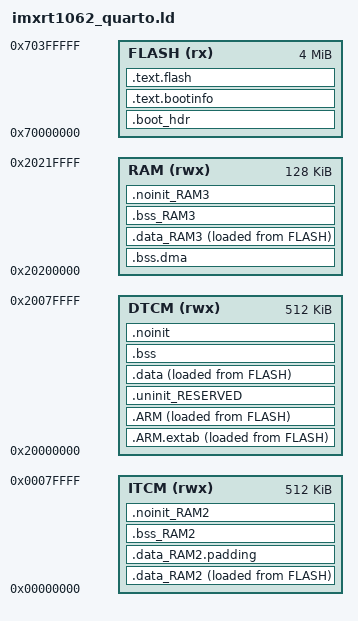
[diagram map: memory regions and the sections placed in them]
MEMORY
{
  	ITCM (rwx) : ORIGIN = 0x0, LENGTH = 0x80000      
  	DTCM (rwx) : ORIGIN = 0x20000000, LENGTH = 0x80000
  	RAM (rwx) : ORIGIN = 0x20200000, LENGTH = 0x20000
  	FLASH (rx) : ORIGIN = 0x70000000, LENGTH = 0x400000
}

ENTRY(ResetHandler)

GROUP (
  "libm.a"
  "libgcc.a"
  "libc_nano.a"
  "libstdc++.a"
 /*  "libcr_newlib_semihost.a"*/
)

SECTIONS
{
     /* Image Vector Table and Boot Data for booting from external flash */
    .boot_hdr : ALIGN(4)
    {
        FILL(0xff)
        __boot_hdr_start__ = ABSOLUTE(.) ;
        KEEP(*(.boot_hdr.conf))
        . = 0x1000 ;
        KEEP(*(.boot_hdr.ivt))
        . = 0x1020 ;
        KEEP(*(.boot_hdr.boot_data))
        . = 0x1030 ;
        KEEP(*(.boot_hdr.dcd_data))
        __boot_hdr_end__ = ABSOLUTE(.) ;
    } >FLASH

    /* MAIN TEXT SECTION */
    .text.bootinfo : ALIGN(4)
    {
        FILL(0xff)
        __vectors_start__ = ABSOLUTE(.) ;
        KEEP(*(.isr_vector))
        /* Global Section Table */
        . = ALIGN(4) ;
        __section_table_start = .;
        __data_section_table = .;
        
        
        LONG(LOADADDR(.data));
        LONG(    ADDR(.data));
        LONG(  SIZEOF(.data));
        LONG(LOADADDR(.data_RAM2));
        LONG(    ADDR(.data_RAM2));
        LONG(  SIZEOF(.data_RAM2));
        LONG(LOADADDR(.data_RAM3));
        LONG(    ADDR(.data_RAM3));
        LONG(  SIZEOF(.data_RAM3));
        __data_section_table_end = .;
        __bss_section_table = .;
        LONG(    ADDR(.bss));
        LONG(  SIZEOF(.bss));
        LONG(    ADDR(.bss_RAM2));
        LONG(  SIZEOF(.bss_RAM2));
        LONG(    ADDR(.bss_RAM3));
        LONG(  SIZEOF(.bss_RAM3));
        __bss_section_table_end = .;
        __section_table_end = . ;
        /* End of Global Section Table */
				
        *(.after_vectors*)
        *(.startup*)

    } > FLASH

    .text.flash : ALIGN(4)
    {       
       *(.progmem*)   
       *(.flashmem*)           
       . = ALIGN(4);
       
        KEEP(*(.init))
        __preinit_array_start = .;
        KEEP (*(.preinit_array))
        __preinit_array_end = .;
        __init_array_start = .;
        KEEP (*(.init_array))
        __init_array_end = .;
        . = ALIGN(16);
              
    } > FLASH
    /*
     * for exception handling/unwind - some Newlib functions (in common
     * with C++ and STDC++) use this.
     */
     
     .bss.dma (NOLOAD) : {
     	*(.dmabuffers)
     	. = ALIGN(16);
     } > RAM
     
     
     
    .ARM.extab : ALIGN(4)
    {
        *(.ARM.extab* .gnu.linkonce.armextab.*)
    } > DTCM AT >FLASH 
    
    
     .ARM : ALIGN(4)
    {
        __exidx_start = .;
        *(.ARM.exidx* .gnu.linkonce.armexidx.*)
        __exidx_end = .;
     } > DTCM AT >FLASH 
 	
     
    _etext = .;
        
    /* DATA section for SRAM_ITC */

    .data_RAM2 : ALIGN(4)
    {
        FILL(0xff)
        PROVIDE(__start_data_RAM2 = .) ;
        PROVIDE(__start_data_SRAM_ITC = .) ;       
        *(.fastrun)		
		*(.text*)		
        *(.ramfunc.$RAM2)
        *(.ramfunc.$SRAM_ITC)        
        *(.data.$RAM2)      
        *(.data.$SRAM_ITC)      
        *(.data.$RAM2.*)        
        *(.data.$SRAM_ITC.*)       
        . = ALIGN(4) ;        
        PROVIDE(__end_data_RAM2 = .) ;
        PROVIDE(__end_data_SRAM_ITC = .) ;
      } > ITCM AT>FLASH 
     

    /* DATA section for SRAM_OC */

 	.data_RAM2.padding  (NOLOAD) : {
		. = ALIGN(32768);		
	} > ITCM
 	


    .data_RAM3 : ALIGN(4)
    {
        FILL(0xff)
        PROVIDE(__start_data_RAM3 = .) ;
        PROVIDE(__start_data_SRAM_OC = .) ;
        *(.ramfunc.$RAM3)
        *(.ramfunc.$SRAM_OC)
        *(.data.$RAM3)
        *(.data.$SRAM_OC)
        *(.data.$RAM3.*)
        *(.data.$SRAM_OC.*)
        . = ALIGN(4) ;
        PROVIDE(__end_data_RAM3 = .) ;
        PROVIDE(__end_data_SRAM_OC = .) ;
     } > RAM AT>FLASH

    /* MAIN DATA SECTION */
    .uninit_RESERVED (NOLOAD) : ALIGN(4)
    {
        _start_uninit_RESERVED = .;
        KEEP(*(.bss.$RESERVED*))
       . = ALIGN(4) ;
        _end_uninit_RESERVED = .;
    } > DTCM AT> DTCM

    /* Main DATA section (SRAM_DTC) */
    .data : ALIGN(4)
    {
       FILL(0xff)
       _data = . ;
       PROVIDE(__start_data_RAM = .) ;
       PROVIDE(__start_data_SRAM_DTC = .) ;
       *(.vectors)
       *(vtable)
       *(.ramfunc*)
       KEEP(*(CodeQuickAccess))
       KEEP(*(DataQuickAccess))
       *(RamFunction)
       *(NonCacheable.init)       
       *(.data*)
       *(.rodata .rodata.* .constdata .constdata.*)       
       . = ALIGN(4) ;
       _edata = . ;
       PROVIDE(__end_data_RAM = .) ;
       PROVIDE(__end_data_SRAM_DTC = .) ;       	
       PROVIDE(__end_data_SRAM_DTC_PADDING = .) ;
    } > DTCM AT>FLASH

    /* BSS section for SRAM_ITC */
    .bss_RAM2 : ALIGN(4)
    {
       PROVIDE(__start_bss_RAM2 = .) ;
       PROVIDE(__start_bss_SRAM_ITC = .) ;
       *(.bss.$RAM2)
       *(.bss.$SRAM_ITC)
       *(.bss.$RAM2.*)
       *(.bss.$SRAM_ITC.*)
       . = ALIGN (. != 0 ? 4 : 1) ; /* avoid empty segment */
       PROVIDE(__end_bss_RAM2 = .) ;
       PROVIDE(__end_bss_SRAM_ITC = .) ;
    } > ITCM AT> ITCM

    /* BSS section for SRAM_OC */
    .bss_RAM3 : ALIGN(4)
    {
       PROVIDE(__start_bss_RAM3 = .) ;
       PROVIDE(__start_bss_SRAM_OC = .) ;
       *(.bss.$RAM3)
       *(.bss.$SRAM_OC)
       *(.bss.$RAM3.*)
       *(.bss.$SRAM_OC.*)
       . = ALIGN (. != 0 ? 4 : 1) ; /* avoid empty segment */
       PROVIDE(__end_bss_RAM3 = .) ;
       PROVIDE(__end_bss_SRAM_OC = .) ;
    } > RAM AT> RAM

    /* MAIN BSS SECTION */
    .bss (NOLOAD) : ALIGN(4)
    {
        _bss = .;
        __bss_start__ = .;
        PROVIDE(__start_bss_RAM = .) ;
        PROVIDE(__start_bss_SRAM_DTC = .) ;
       *(NonCacheable)
        *(.bss*)
        *(COMMON)
        . = ALIGN(4) ;
        _ebss = .;
        __bss_end__ = .;
        PROVIDE(__end_bss_RAM = .) ;
        PROVIDE(__end_bss_SRAM_DTC = .) ;
        PROVIDE(end = .);
        . +=  _itcm_block_count*0x8000; /* inrease by ITCM size since DTCM smaller by this amount */
        PROVIDE(__end_bss_SRAM_DTC_plusCutout = .) ;
    } > DTCM AT> DTCM

    /* NOINIT section for SRAM_ITC */
    .noinit_RAM2 (NOLOAD) : ALIGN(4)
    {
       PROVIDE(__start_noinit_RAM2 = .) ;
       PROVIDE(__start_noinit_SRAM_ITC = .) ;
       *(.noinit.$RAM2)
       *(.noinit.$SRAM_ITC)
       *(.noinit.$RAM2.*)
       *(.noinit.$SRAM_ITC.*)
       . = ALIGN(4) ;
       PROVIDE(__end_noinit_RAM2 = .) ;
       PROVIDE(__end_noinit_SRAM_ITC = .) ;
    } > ITCM AT> ITCM

    /* NOINIT section for SRAM_OC */
    .noinit_RAM3 (NOLOAD) : ALIGN(4)
    {
       PROVIDE(__start_noinit_RAM3 = .) ;
       PROVIDE(__start_noinit_SRAM_OC = .) ;
       *(.noinit.$RAM3)
       *(.noinit.$SRAM_OC)
       *(.noinit.$RAM3.*)
       *(.noinit.$SRAM_OC.*)
       . = ALIGN(4) ;
       PROVIDE(__end_noinit_RAM3 = .) ;
       PROVIDE(__end_noinit_SRAM_OC = .) ;
    } > RAM AT> RAM

    /* DEFAULT NOINIT SECTION */
    .noinit (NOLOAD): ALIGN(4)
    {
        _noinit = .;
        PROVIDE(__start_noinit_RAM = .) ;
        PROVIDE(__start_noinit_SRAM_DTC = .) ;
        *(.noinit*)
         . = ALIGN(4) ;
        _end_noinit = .;
       PROVIDE(__end_noinit_RAM = .) ;
       PROVIDE(__end_noinit_SRAM_DTC = .) ;        
    } > DTCM AT> DTCM

    _itcm_block_count = (SIZEOF(.data_RAM2) + 0x7FFF) >> 15;
	_flexram_bank_config = 0xAAAAAAAA | ((1 << (_itcm_block_count * 2)) - 1);
	_estack = ORIGIN(DTCM) + ((16 - _itcm_block_count) << 15) - 32;
    _vStackTop = 0x2001f000; /* Initial Stack pointer */
     _heap_start = ADDR(.bss.dma) + SIZEOF(.bss.dma);
    _heap_end = ORIGIN(RAM) + LENGTH(RAM);
    
    
}
